# XHSC_HC32L12X register map
Vendor: XHSC Co.Ltd; Series: ARMCM0P; File version: 1.0
CPU: CM0P r0p0, little endian, no MPU, no FPU, 3 interrupt priority bits
Registers are 32-bit, read-write, reset 0x0 unless marked. A register's access mark holds for its fields unless they carry their own. Offsets are from the block's base; lines under a group give offsets from that group; [hi:lo] are bit positions; {n}, {i} and the like mark numbered series; 'fields as' and 'values as' point back to an identical list; <NAME> marks a mode.

## Memory map
0x40000000 LPUART0 size 0x24 — desc LPUART
0x40000400 I2C0 size 0x2C — desc I2C
0x40000800 SPI0 size 0x1C — desc SPI
0x40000C00 LPTIMER0 size 0x18 — desc LPTIMER
0x40001080 IWDT size 0x14
0x40001400 RTC size 0x64
0x40002400 ADC size 0xD0
0x40002800 VC0 size 0x10 — desc VC
0x40002810 VC1 size 0x10 — desc VC
0x40002820 VCTRIM size 0x4
0x40002C00 LVD size 0x30
0x40003000 TIM0_MODE0 size 0x34
0x40003000 TIM0_MODE1 size 0x40
0x40003000 TIM0_MODE23 size 0x44
0x40003400 TIM1_MODE0 size 0x34
0x40003400 TIM1_MODE1 size 0x40
0x40003400 TIM1_MODE23 size 0x44
0x40003800 TIM2_MODE0 size 0x34
0x40003800 TIM2_MODE1 size 0x40
0x40003800 TIM2_MODE23 size 0x44
0x40003C00 LPTIMER1 size 0x18 — desc LPTIMER
0x40008000 LPUART1 size 0x24 — desc LPUART
0x40008400 I2C1 size 0x2C — desc I2C
0x40008800 SPI1 size 0x1C — desc SPI
0x40008C00 TRNG size 0x14
0x40009000 CTRIM size 0x2C
0x40009800 TIM3_MODE0 size 0x34
0x40009800 TIM3_MODE1 size 0x40
0x40009800 TIM3_MODE23 size 0x64
0x40009C00 LCD size 0x80
0x4000A000 USART0 size 0xF4 — desc USART
0x4000A400 USART1 size 0xF4 — desc USART
0x4000B400 LPUART2 size 0x24 — desc LPUART
0x4000B800 WWDT size 0xC
0x4000BC00 HSI2C size 0x174
0x40020000 FLASH size 0x70
0x40020400 RAM size 0x10
0x40020800 CRC size 0x84
0x40020C00 GPIO size 0x1254
0x40021000 DMAC size 0x30
0x40021400 AES size 0x44
0x40021800 SYSCTRL size 0x3C
0x4002181C RESET size 0x14
0x40021838 DEBUG_ACTIVE size 0x4

## ADC
Base 0x40002400
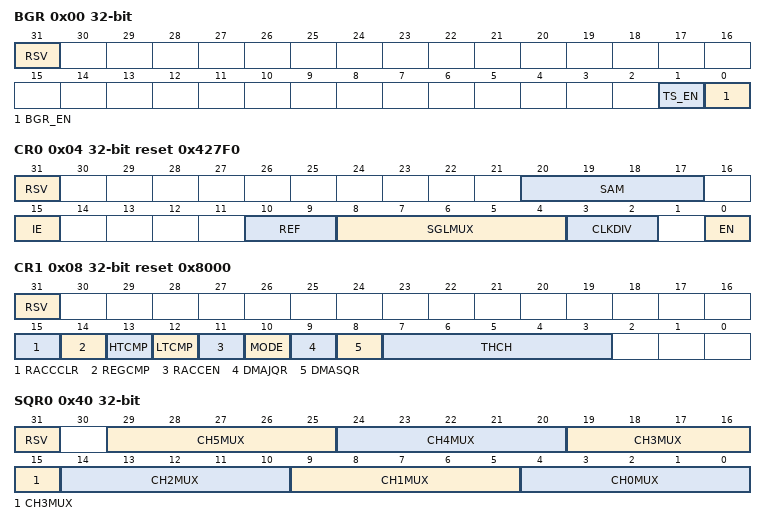
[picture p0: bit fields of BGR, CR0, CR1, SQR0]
0x00 BGR (reset mask 0x3)
  [31] RSV, [1] TS_EN, [0] BGR_EN
0x04 CR0 reset 0x427F0 (reset mask 0x1E8FFD)
  [31] RSV, [20:17] SAM, [15] IE, [10:9] REF, [8:4] SGLMUX, [3:2] CLKDIV, [0] EN
0x08 CR1 reset 0x8000 (reset mask 0xFFF1)
  [31] RSV, [15] RACCCLR wo, [14] REGCMP, [13] HTCMP, [12] LTCMP, [11] RACCEN, [10] MODE, [9] DMAJQR, [8] DMASQR, [7:3] THCH
0x40 SQR0 (reset mask 0x3FFFFFFF)
  [31] RSV, [5n+4:5n] CH{n}MUX (n=0..5)
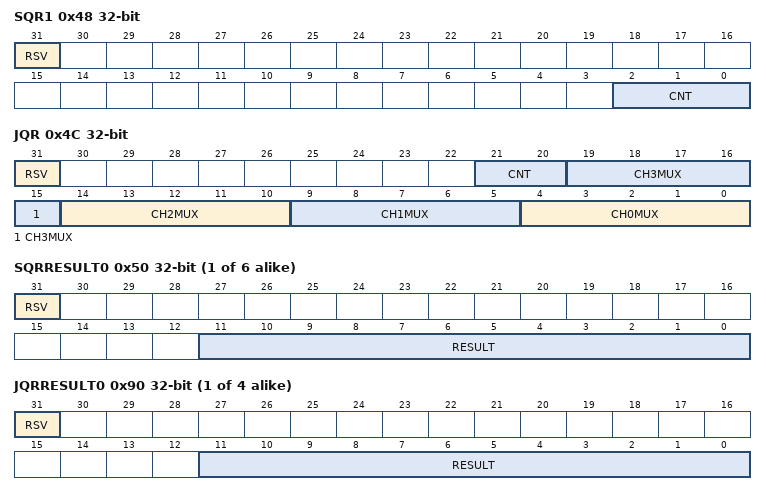
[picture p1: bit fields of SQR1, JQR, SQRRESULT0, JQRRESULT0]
0x48 SQR1 (reset mask 0x7)
  [31] RSV, [2:0] CNT
0x4C JQR (reset mask 0x3FFFFF)
  [31] RSV, [21:20] CNT, [5n+4:5n] CH{n}MUX (n=0..3)
{0x50+4i} SQRRESULT{i} ro (reset mask 0xFFF) (i=0..5)
  [31] RSV rw, [11:0] RESULT
{0x90+4i} JQRRESULT{i} ro (reset mask 0xFFF) (i=0..3)
  [31] RSV rw, [11:0] RESULT
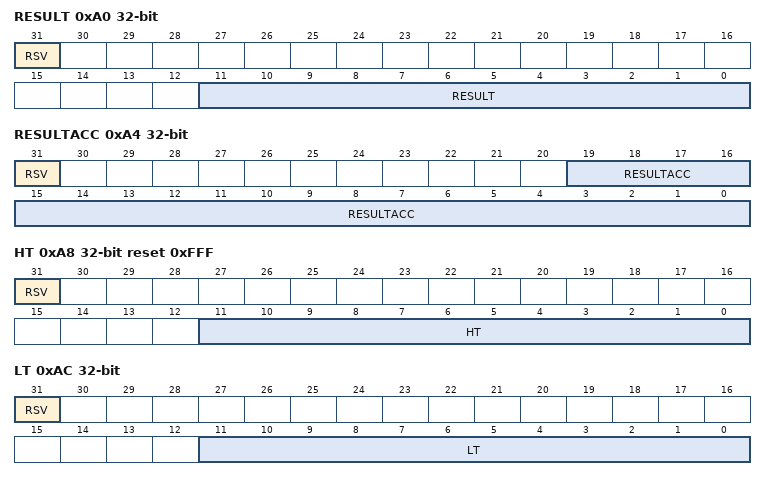
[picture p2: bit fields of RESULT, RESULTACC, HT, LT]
0xA0 RESULT ro (reset mask 0xFFF)
  [31] RSV rw, [11:0] RESULT
0xA4 RESULTACC ro (reset mask 0xFFFFF)
  [31] RSV rw, [19:0] RESULTACC
0xA8 HT reset 0xFFF (reset mask 0xFFF)
  [31] RSV, [11:0] HT
0xAC LT (reset mask 0xFFF)
  [31] RSV, [11:0] LT
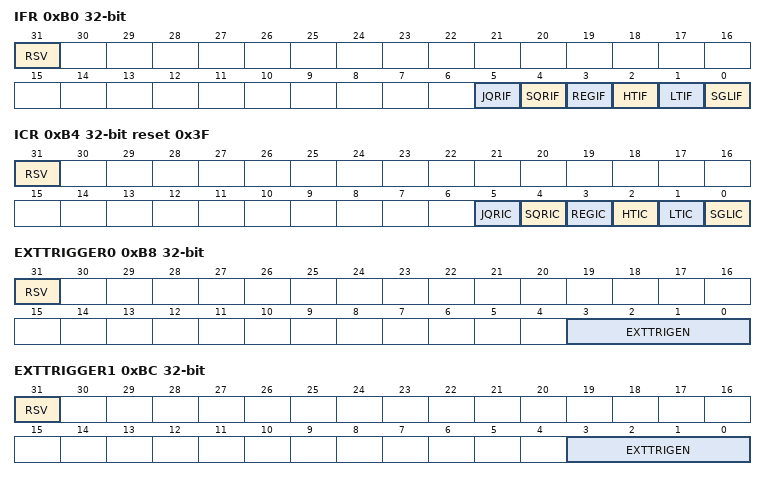
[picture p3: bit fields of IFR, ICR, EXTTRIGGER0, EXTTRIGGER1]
0xB0 IFR ro (reset mask 0x3F)
  [31] RSV rw, [5] JQRIF, [4] SQRIF, [3] REGIF, [2] HTIF, [1] LTIF, [0] SGLIF
0xB4 ICR wo reset 0x3F (reset mask 0x3F)
  [31] RSV rw, [5] JQRIC, [4] SQRIC, [3] REGIC, [2] HTIC, [1] LTIC, [0] SGLIC
0xB8 EXTTRIGGER0 (reset mask 0xFFFF)
  [31] RSV, [3:0] EXTTRIGEN
0xBC EXTTRIGGER1 (reset mask 0xFFFF)
  [31] RSV, [3:0] EXTTRIGEN
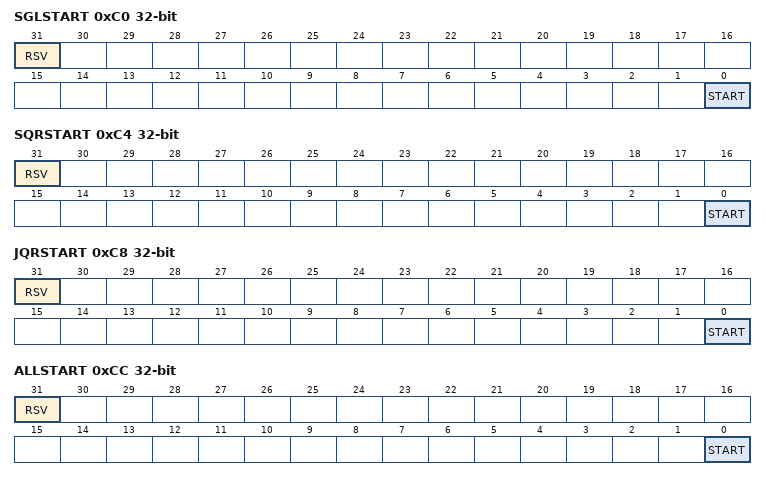
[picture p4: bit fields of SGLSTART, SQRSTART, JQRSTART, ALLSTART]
0xC0 SGLSTART (reset mask 0x1)
  [31] RSV, [0] START
0xC4 SQRSTART (reset mask 0x1)
  [31] RSV, [0] START
0xC8 JQRSTART (reset mask 0x1)
  [31] RSV, [0] START
0xCC ALLSTART (reset mask 0x1)
  [31] RSV, [0] START

## AES
Base 0x40021400
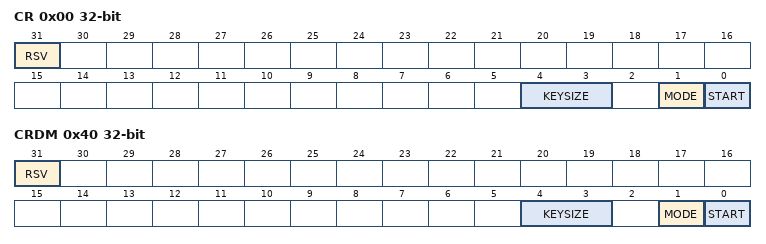
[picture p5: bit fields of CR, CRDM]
0x00 CR (reset mask 0x1B)
  [31] RSV, [4:3] KEYSIZE, [1] MODE, [0] START
{0x10+4i} DATA{i} (i=0..3)
  [31:0] DATA
{0x20+4i} KEY{i} (i=0..7)
  [31:0] KEY
0x40 CRDM (reset mask 0x1B)
  [31] RSV, [4:3] KEYSIZE, [1] MODE, [0] START

## CRC
Base 0x40020800
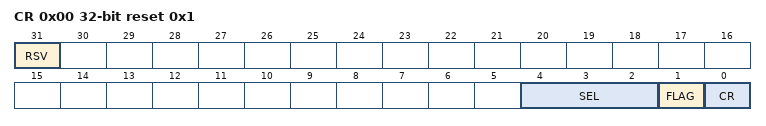
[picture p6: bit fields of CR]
0x00 CR reset 0x1 (reset mask 0x3)
  [31] RSV ro, [4:2] SEL, [1] FLAG ro, [0] CR
0x04 RESULT
0x80 DATA wo

## CTRIM
Base 0x40009000
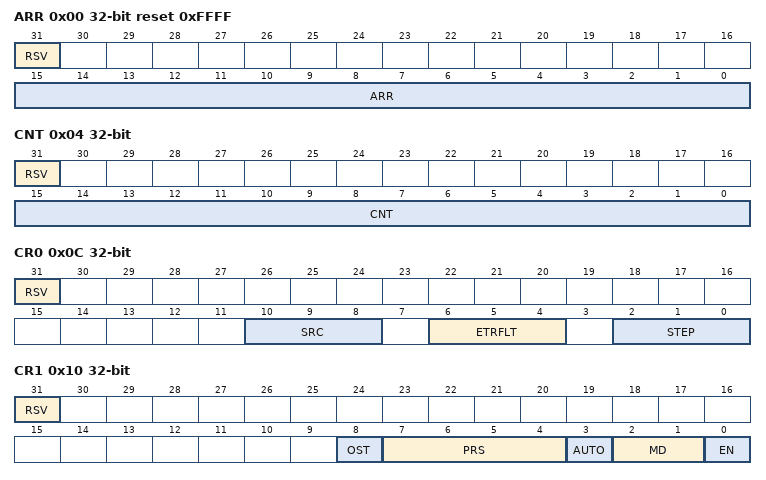
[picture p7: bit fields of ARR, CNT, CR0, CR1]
0x00 ARR reset 0xFFFF (reset mask 0xFFFF)
  [31] RSV, [15:0] ARR
0x04 CNT ro (reset mask 0xFFFF)
  [31] RSV, [15:0] CNT
0x0C CR0 (reset mask 0x777)
  [31] RSV, [10:8] SRC, [6:4] ETRFLT, [2:0] STEP
0x10 CR1 (reset mask 0x7FF)
  [31] RSV, [8] OST, [7:4] PRS, [3] AUTO, [2:1] MD, [0] EN
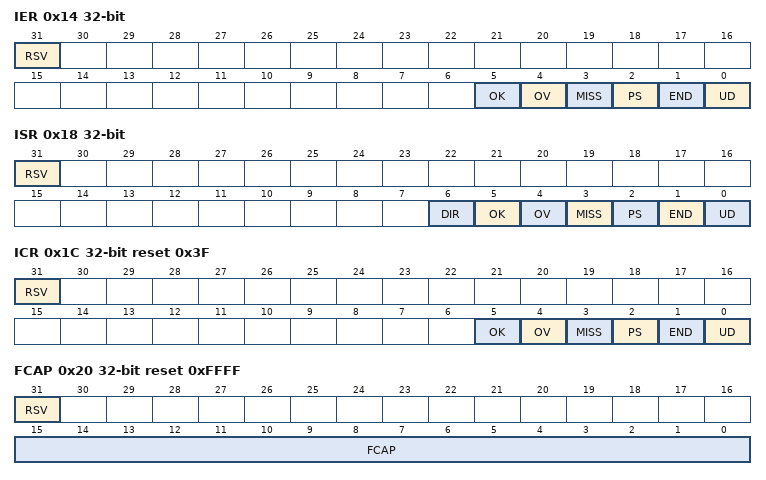
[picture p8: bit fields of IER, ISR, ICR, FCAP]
0x14 IER (reset mask 0x3F)
  [31] RSV, [5] OK, [4] OV, [3] MISS, [2] PS, [1] END, [0] UD
0x18 ISR ro (reset mask 0x7F)
  [31] RSV, [6] DIR, [5] OK, [4] OV, [3] MISS, [2] PS, [1] END, [0] UD
0x1C ICR wo reset 0x3F (reset mask 0x3F)
  [31] RSV, [5] OK, [4] OV, [3] MISS, [2] PS, [1] END, [0] UD
0x20 FCAP ro reset 0xFFFF (reset mask 0xFFFF)
  [31] RSV, [15:0] FCAP
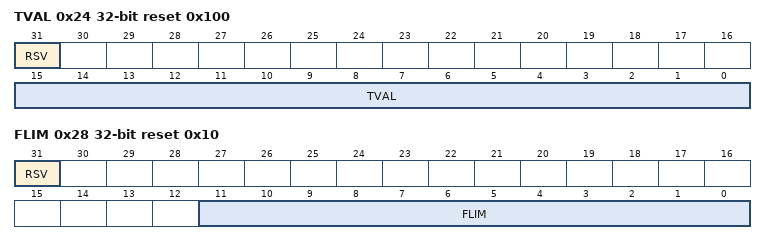
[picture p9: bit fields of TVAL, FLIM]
0x24 TVAL ro reset 0x100 (reset mask 0xFFFF)
  [31] RSV, [15:0] TVAL
0x28 FLIM reset 0x10 (reset mask 0xFFF)
  [31] RSV, [11:0] FLIM
